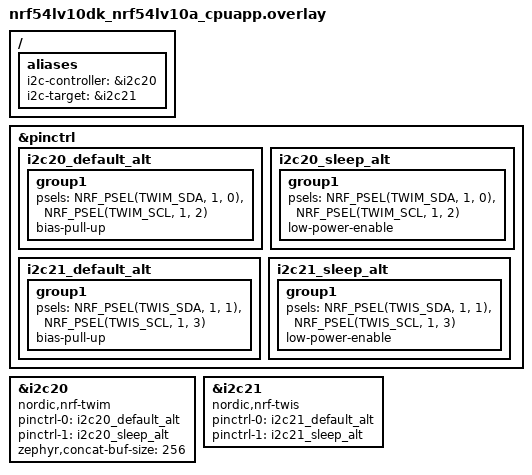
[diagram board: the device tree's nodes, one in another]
/*
 * Copyright (c) 2026 Nordic Semiconductor ASA
 *
 * SPDX-License-Identifier: LicenseRef-Nordic-5-Clause
 */

/*
 * SDA = P1.0 and P1.1
 * SCL = P1.2 and P1.3
 */

/ {
	aliases {
		i2c-controller = &i2c20;
		i2c-target = &i2c21;
	};
};

&pinctrl {
	i2c20_default_alt: i2c20_default_alt {
		group1 {
			psels = <NRF_PSEL(TWIM_SDA, 1, 0)>,
				<NRF_PSEL(TWIM_SCL, 1, 2)>;
			bias-pull-up;
		};
	};

	i2c20_sleep_alt: i2c20_sleep_alt {
		group1 {
			psels = <NRF_PSEL(TWIM_SDA, 1, 0)>,
				<NRF_PSEL(TWIM_SCL, 1, 2)>;
			low-power-enable;
		};
	};

	i2c21_default_alt: i2c21_default_alt {
		group1 {
			psels = <NRF_PSEL(TWIS_SDA, 1, 1)>,
				<NRF_PSEL(TWIS_SCL, 1, 3)>;
			bias-pull-up;
		};
	};

	i2c21_sleep_alt: i2c21_sleep_alt {
		group1 {
			psels = <NRF_PSEL(TWIS_SDA, 1, 1)>,
				<NRF_PSEL(TWIS_SCL, 1, 3)>;
			low-power-enable;
		};
	};
};

&i2c20 {
	compatible = "nordic,nrf-twim";
	pinctrl-0 = <&i2c20_default_alt>;
	pinctrl-1 = <&i2c20_sleep_alt>;
	pinctrl-names = "default", "sleep";
	zephyr,concat-buf-size = <256>;
	status = "okay";
};

&i2c21 {
	compatible = "nordic,nrf-twis";
	pinctrl-0 = <&i2c21_default_alt>;
	pinctrl-1 = <&i2c21_sleep_alt>;
	pinctrl-names = "default", "sleep";
	status = "okay";
};
